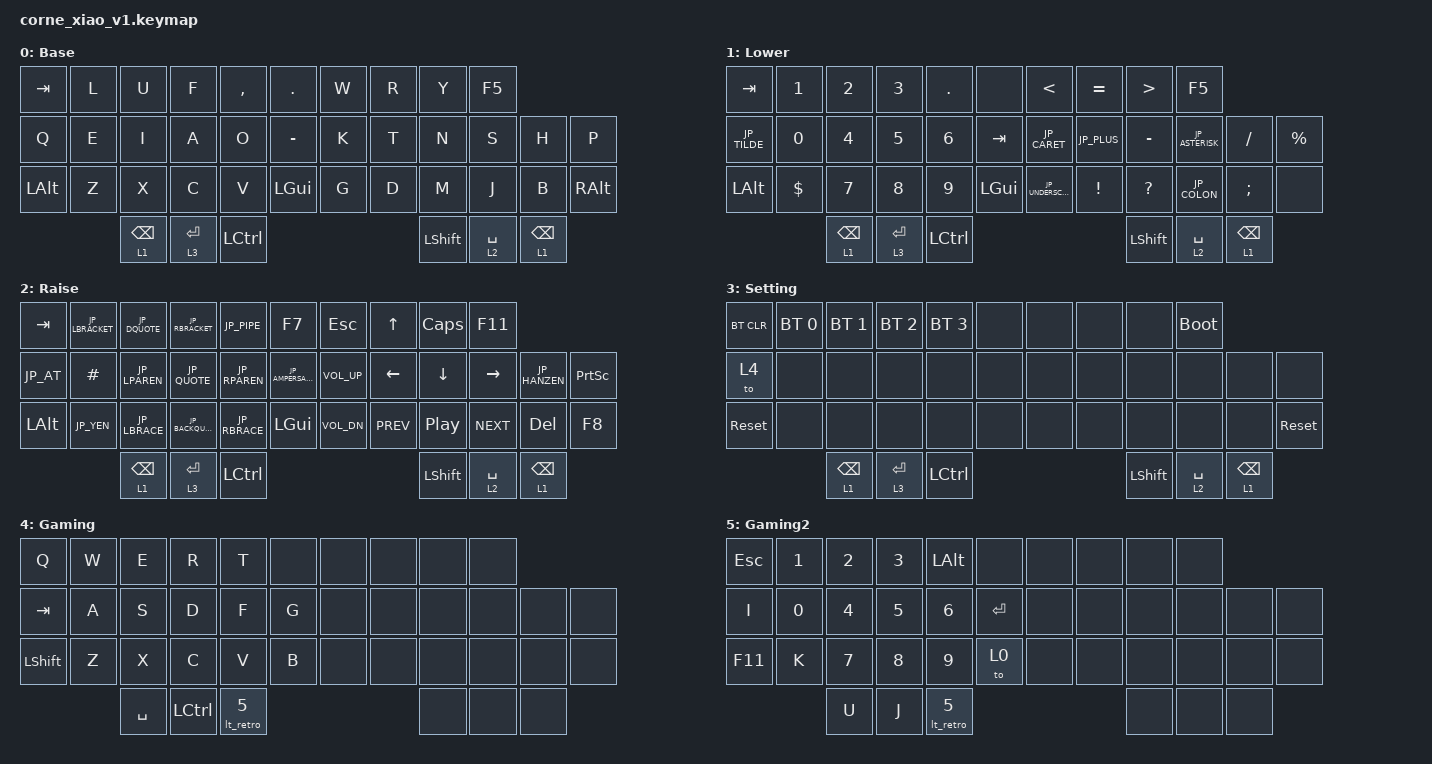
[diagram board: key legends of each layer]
// OS設定を日本語キーボードのまま使用するための変換定義
#define JP_DQUOTE       AT                // "
#define JP_AMPERSAND    CARET             // &
#define JP_QUOTE        AMPERSAND         // '
#define JP_EQUAL        UNDER             // =
#define JP_CARET        EQUAL             // ^
#define JP_YEN          0x89              // ¥
#define JP_PLUS         COLON             // +
#define JP_TILDE        PLUS              // ~
#define JP_PIPE         LS(0x89)          // |
#define JP_AT           LEFT_BRACKET      // @
#define JP_COLON        SINGLE_QUOTE      // :
#define JP_ASTERISK     DOUBLE_QUOTES     // *
#define JP_BACKQUOTE    LEFT_BRACE        // `
#define JP_UNDERSCORE   LS(0x87)          // _
#define JP_LBRACKET     RIGHT_BRACKET     // [
#define JP_RBRACKET     BACKSLASH         // ]
#define JP_LPAREN       ASTERISK          // (
#define JP_RPAREN       LEFT_PARENTHESIS  // )
#define JP_LBRACE       RIGHT_BRACE       // {
#define JP_RBRACE       PIPE              // }
#define JP_KANA         LANGUAGE_1        // かな
#define JP_EISU         LANGUAGE_2        // 英数
#define JP_HANZEN       GRAVE             // 半角/全角

/* boards/shields/corne_xiao_v1/corne_xiao_v1.keymap */
#include <behaviors.dtsi>
#include <dt-bindings/zmk/keys.h>
#include <dt-bindings/zmk/bt.h>

/ {
    behaviors {
        lt_retro: layer_tap_retro {
            compatible = "zmk,behavior-hold-tap";
            label = "LAYER_TAP_RETRO";
            #binding-cells = <2>;
            flavor = "tap-preferred";
            tapping-term-ms = <100>;
            quick-tap-ms = <175>;
            retro-tap;
            bindings = <&mo>, <&kp>;
        };
    };

    combos {
        compatible = "zmk,combos";
        combo_studio_unlock {
            timeout-ms = <50>;
            key-positions = <0 1>;
            bindings = <&studio_unlock>;
        };
        combo_bootloader_l {
            timeout-ms = <50>;
            key-positions = <0 10 22>;
            bindings = <&bootloader>;
        };
        combo_bootloader_r {
            timeout-ms = <50>;
            key-positions = <9 21 33>;
            bindings = <&bootloader>;
        };
        combo_sys_reset_l {
            timeout-ms = <50>;
            key-positions = <4 15 27>;
            bindings = <&sys_reset>;
        };
        combo_sys_reset_r {
            timeout-ms = <50>;
            key-positions = <5 16 28>;
            bindings = <&sys_reset>;
        };
    };

    keymap {
        compatible = "zmk,keymap";

//0
        default_layer {
            display-name = "Base";
            bindings = <
    /* 上段 (10キー) */
    &kp TAB   &kp L     &kp U     &kp F     &kp COMMA      &kp DOT  &kp W     &kp R     &kp Y     &kp F5
    /* 中段 (12キー) */
    &kp Q     &kp E     &kp I     &kp A     &kp O     &kp MINUS    &kp K     &kp T     &kp N     &kp S     &kp H     &kp P
    /* 下段 (12キー) */
    &kp LALT  &kp Z     &kp X     &kp C     &kp V     &kp LGUI     &kp G     &kp D     &kp M     &kp J     &kp B     &kp RALT
    /* 親指 */
                        &lt_retro 1 BSPC &lt_retro 3 RET  &kp LCTRL       &kp LSHIFT  &lt_retro 2 SPACE &lt_retro 1 BSPC
            >;
        };

//1
        lower_layer {
            display-name = "Lower";
            bindings = <
    &kp TAB &kp N1  &kp N2  &kp N3  &kp DOT         &none    &kp LESS_THAN   &kp EQUAL   &kp GREATER_THAN    &kp F5
    &kp JP_TILDE &kp N0    &kp N4  &kp N5  &kp N6  &kp TAB         &kp JP_CARET   &kp JP_PLUS    &kp MINUS   &kp JP_ASTERISK   &kp FSLH    &kp PRCNT
    &kp LALT
    &kp DOLLAR  &kp N7  &kp N8  &kp N9  &kp LGUI    &kp JP_UNDERSCORE &kp EXCL  &kp QMARK &kp JP_COLON &kp SEMI    &none
                        &lt_retro 1 BSPC &lt_retro 3 RET  &kp LCTRL       &kp LSHIFT  &lt_retro 2 SPACE &lt_retro 1 BSPC
            >;
        };

//2
        raise_layer {
            display-name = "Raise";
            bindings = <
    &kp TAB   &kp JP_LBRACKET   &kp JP_DQUOTE   &kp JP_RBRACKET  &kp JP_PIPE       &kp F7  &kp ESC &kp UP &kp CAPSLOCK &kp F11
    &kp JP_AT &kp HASH  &kp JP_LPAREN  &kp JP_QUOTE   &kp JP_RPAREN  &kp JP_AMPERSAND     &kp C_VOL_UP &kp LEFT &kp DOWN  &kp RIGHT &kp JP_HANZEN &kp PSCRN
    &kp LALT  &kp JP_YEN  &kp JP_LBRACE &kp JP_BACKQUOTE &kp JP_RBRACE  &kp LGUI     &kp C_VOL_DN &kp C_PREV &kp C_PP  &kp C_NEXT &kp DEL   &kp F8
                        &lt_retro 1 BSPC &lt_retro 3 RET  &kp LCTRL       &kp LSHIFT  &lt_retro 2 SPACE &lt_retro 1 BSPC
            >;
        };


//3
        setting_layer {
            display-name = "Setting";
            bindings = <
    &bt BT_CLR   &bt BT_SEL 0   &bt BT_SEL 1   &bt BT_SEL 2  &bt BT_SEL 3       &none  &none &none &none &bootloader
    &to 4 &none  &none  &none   &none  &none     &none &none &none  &none &none &none
    &sys_reset  &none  &none &none &none  &none     &none &none &none  &none &none   &sys_reset
                        &lt_retro 1 BSPC &lt_retro 3 RET  &kp LCTRL       &kp LSHIFT  &lt_retro 2 SPACE &lt_retro 1 BSPC
            >;
        };

//4
        gaming_layer {
            display-name = "Gaming";
            bindings = <
    &kp Q   &kp W   &kp E   &kp R  &kp T       &none  &none &none &none &none
    &kp TAB &kp A  &kp S  &kp D   &kp F  &kp G     &none &none &none  &none &none &none
    &kp LSHIFT  &kp Z  &kp X &kp C &kp V  &kp B     &none &none &none  &none &none   &none
                        &kp SPACE &kp LCTRL  &lt_retro 5       &none  &none &none
            >;
        };
        
//5
        gaming_layer2 {
            display-name = "Gaming2";
            bindings = <
    &kp ESC   &kp N1   &kp N2   &kp N3  &kp LALT       &none  &none &none &none &none
    &kp I &kp N0  &kp N4  &kp N5   &kp N6  &kp RET     &none &none &none  &none &none &none
    &kp F11  &kp K  &kp N7 &kp N8 &kp N9  &to 0     &none &none &none  &none &none   &none
                        &kp U &kp J  &lt_retro 5       &none  &none &none
            >;
        };

        extra1 { status = "reserved"; };
        extra2 { status = "reserved"; };
    };
};

/* I2C無効化 */
&i2c0 { status = "disabled"; };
